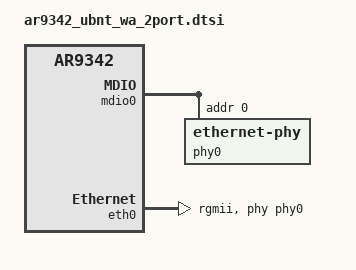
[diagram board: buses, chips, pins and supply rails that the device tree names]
// SPDX-License-Identifier: GPL-2.0-only

#include "ar9342_ubnt_wa.dtsi"

&mdio0 {
	status = "okay";

	phy-mask = <4>;

	phy0: ethernet-phy@0 {
		phy-mode = "rgmii";
		reg = <0>;

		qca,ar8327-initvals = <
			0x04 0x07600000 /* PORT0 PAD MODE CTRL */
			0x58 0xffb7ffb7 /* LED_CTRL2 */
			0x5c 0x03ffff00 /* LED_CTRL3 */
			0x7c 0x0000007e /* PORT0_STATUS */
		>;
	};
};

&eth0 {
	status = "okay";

	/* default for ar934x, except for 1000M and 10M */
	pll-data = <0x06000000 0x00000101 0x00001313>;

	nvmem-cells = <&macaddr_art_0>;
	nvmem-cell-names = "mac-address";

	phy-mode = "rgmii";
	phy-handle = <&phy0>;

	gmac-config {
		device = <&gmac>;
		rxd-delay = <2>;
		rxdv-delay = <2>;
	};
};
